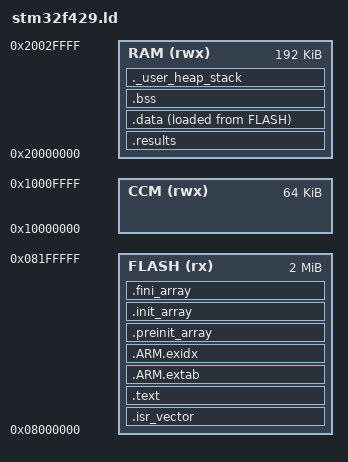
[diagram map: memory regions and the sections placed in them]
/* STM32F429ZI: 2 MB flash, 192 KB SRAM (SRAM1+2+3 contiguous), 64 KB CCM. */
MEMORY
{
  FLASH (rx)  : ORIGIN = 0x08000000, LENGTH = 2048K
  RAM   (rwx) : ORIGIN = 0x20000000, LENGTH = 192K
  CCM   (rwx) : ORIGIN = 0x10000000, LENGTH = 64K
}

_estack = ORIGIN(RAM) + LENGTH(RAM);

SECTIONS
{
  .isr_vector : { KEEP(*(.isr_vector)) } > FLASH

  .text :
  {
    . = ALIGN(4);
    *(.text .text.*)
    *(.rodata .rodata.*)
    *(.glue_7) *(.glue_7t) *(.eh_frame)
    KEEP(*(.init)) KEEP(*(.fini))
    . = ALIGN(4);
    _etext = .;
  } > FLASH

  .ARM.extab : { *(.ARM.extab* .gnu.linkonce.armextab.*) } > FLASH
  .ARM.exidx : { __exidx_start = .; *(.ARM.exidx*) __exidx_end = .; } > FLASH

  .preinit_array : { PROVIDE_HIDDEN(__preinit_array_start = .); KEEP(*(.preinit_array*)) PROVIDE_HIDDEN(__preinit_array_end = .); } > FLASH
  .init_array : { PROVIDE_HIDDEN(__init_array_start = .); KEEP(*(SORT(.init_array.*))) KEEP(*(.init_array*)) PROVIDE_HIDDEN(__init_array_end = .); } > FLASH
  .fini_array : { PROVIDE_HIDDEN(__fini_array_start = .); KEEP(*(SORT(.fini_array.*))) KEEP(*(.fini_array*)) PROVIDE_HIDDEN(__fini_array_end = .); } > FLASH

  /* Test results live at the very start of RAM so the harness knows where to look. */
  .results (NOLOAD) :
  {
    . = ALIGN(4);
    KEEP(*(.results))
    . = ALIGN(4);
  } > RAM

  _sidata = LOADADDR(.data);
  .data :
  {
    . = ALIGN(4);
    _sdata = .;
    *(.data .data.*)
    . = ALIGN(4);
    _edata = .;
  } > RAM AT> FLASH

  .bss :
  {
    . = ALIGN(4);
    _sbss = .;
    __bss_start__ = _sbss;
    *(.bss .bss.*)
    *(COMMON)
    . = ALIGN(4);
    _ebss = .;
    __bss_end__ = _ebss;
  } > RAM

  ._user_heap_stack :
  {
    . = ALIGN(8);
    PROVIDE(end = .);
    PROVIDE(_end = .);
    . = . + 0x400;
    . = . + 0x800;
    . = ALIGN(8);
  } > RAM

  /DISCARD/ : { libc.a(*) libm.a(*) libgcc.a(*) }
  .ARM.attributes 0 : { *(.ARM.attributes) }
}
